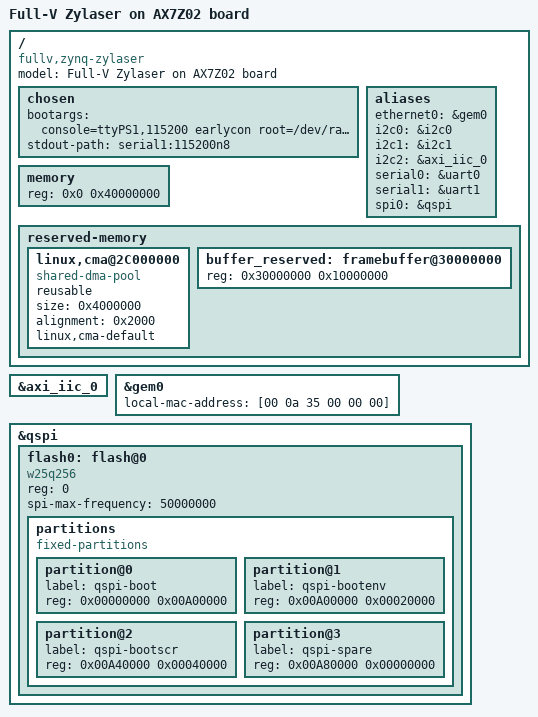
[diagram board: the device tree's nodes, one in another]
/*
 * CAUTION: This file is automatically generated by Xilinx.
 * Version:  
 * Today is: Tue Oct 27 21:13:41 2020
 */

/dts-v1/;
#include "zynq-7000.dtsi"
#include "zynq-zylaser-ax7z02/pl.dtsi"
#include "zynq-zylaser-ax7z02/pcw.dtsi"

/ {
	model = "Full-V Zylaser on AX7Z02 board";
	compatible = "fullv,zynq-zylaser", "xlnx,zynq-7000";

	chosen {
		bootargs = "console=ttyPS1,115200 earlycon root=/dev/ram0 rw";
		stdout-path = "serial1:115200n8";
	};

	aliases {
		ethernet0 = &gem0;
		i2c0 = &i2c0;
		i2c1 = &i2c1;
		i2c2 = &axi_iic_0;
		serial0 = &uart0;
		serial1 = &uart1;
		spi0 = &qspi;
	};

	memory {
		device_type = "memory";
		reg = <0x0 0x40000000>;
	};

	reserved-memory {
		#address-cells = <1>;
		#size-cells = <1>;
		ranges;

		/* 64MB global autoconfigured region for contiguous allocations */
		linux,cma@2C000000 {
			compatible = "shared-dma-pool";
			reusable;
			size = <0x4000000>;
			alignment = <0x2000>;
			linux,cma-default;
		};

		/* 256MB for FPGA */
		buffer_reserved: framebuffer@30000000 {
			reg = <0x30000000 0x10000000>;
		};
	};
};

&axi_iic_0 {
	status = "okay";
};

&gem0 {
	local-mac-address = [00 0a 35 00 00 00];
};

&qspi {
	#address-cells = <1>;
	#size-cells = <0>;

	flash0: flash@0 {
		compatible = "w25q256";
		reg = <0>;
		spi-max-frequency = <50000000>;

		partitions {
			#address-cells = <1>;
			#size-cells = <1>;
			compatible = "fixed-partitions";

			partition@0 {
				label = "qspi-boot";
				reg = <0x00000000 0x00A00000>;
			};
			partition@1 {
				label = "qspi-bootenv";
				reg = <0x00A00000 0x00020000>;
			};
			partition@2 {
				label = "qspi-bootscr";
				reg = <0x00A40000 0x00040000>;
			};
			partition@3 {
				label = "qspi-spare";
				reg = <0x00A80000 0x00000000>;
			};
		};
	};
};
